# STM8S105C6 register map
Vendor: STMicroelectronics; Series: STM8S/STM8AF, medium density; File version: 1.0
CPU: other r1p0, big endian, no MPU, no FPU
Registers are 8-bit, read-write, reset 0x0 unless marked. A register's access mark holds for its fields unless they carry their own. Offsets are from the block's base; [hi:lo] are bit positions; {n}, {i} and the like mark numbered series.

## ITC_EXTI
Base 0x000050A0
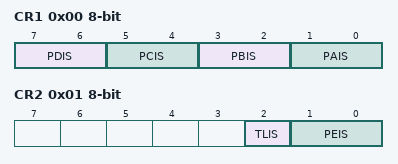
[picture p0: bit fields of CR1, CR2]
0x00 CR1 — External interrupt control register 1
  [7:6] PDIS, [5:4] PCIS, [3:2] PBIS, [1:0] PAIS
0x01 CR2 — External interrupt control register 2
  [2] TLIS, [1:0] PEIS

## ITC_SPR
Base 0x00007F70
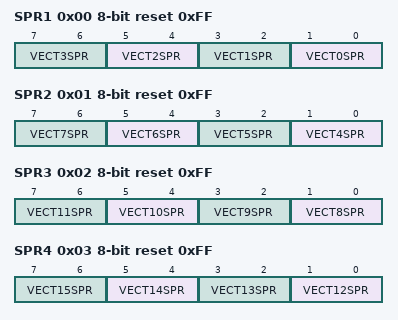
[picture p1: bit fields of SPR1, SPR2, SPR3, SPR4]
0x00 SPR1 reset 0xFF — Interrupt software priority register 1
  [2n+1:2n] VECT{n}SPR (n=0..3)
0x01 SPR2 reset 0xFF — Interrupt software priority register 2
  [2n-7:2n-8] VECT{n}SPR (n=4..7)
0x02 SPR3 reset 0xFF — Interrupt software priority register 3
  [2n-15:2n-16] VECT{n}SPR (n=8..11)
0x03 SPR4 reset 0xFF — Interrupt software priority register 4
  [2n-23:2n-24] VECT{n}SPR (n=12..15)
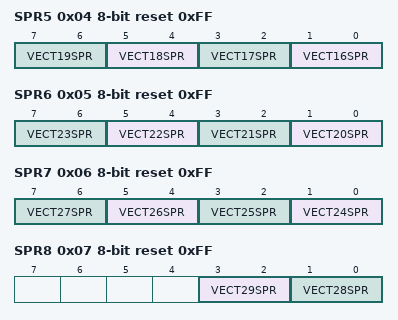
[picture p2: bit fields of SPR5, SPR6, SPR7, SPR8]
0x04 SPR5 reset 0xFF — Interrupt software priority register 5
  [2n-31:2n-32] VECT{n}SPR (n=16..19)
0x05 SPR6 reset 0xFF — Interrupt software priority register 6
  [2n-39:2n-40] VECT{n}SPR (n=20..23)
0x06 SPR7 reset 0xFF — Interrupt software priority register 7
  [2n-47:2n-48] VECT{n}SPR (n=24..27)
0x07 SPR8 reset 0xFF — Interrupt software priority register 8
  [3:2] VECT29SPR, [1:0] VECT28SPR

## IWDG
Base 0x000050E0
0x00 KR — IWDG key register
  [7:0] KEY
0x01 PR — IWDG prescaler register
  [2:0] PR
0x02 RLR reset 0xFF — IWDG reload register
  [7:0] RL

## OPT
Base 0x00004800
0x00 OPT0 — Read-out protection (ROP)
0x01 OPT1 — User boot code (UBC)
0x02 NOPT1 reset 0xFF — User boot code (UBC) (complementary byte)
0x03 OPT2 — Alternate function remapping (AFR)
0x04 NOPT2 reset 0xFF — Alternate function remapping (AFR) (complementary byte)
0x05 OPT3 — Misc. option
0x06 NOPT3 reset 0xFF — Misc. option (complementary byte)
0x07 OPT4 — Clock option
0x08 NOPT4 reset 0xFF — Clock option (complementary byte)
0x09 OPT5 — HSE clock startup
0x0A NOPT5 reset 0xFF — HSE clock startup (complementary byte)
0x7E OPTBL — Bootloader
0x7F NOPTBL reset 0xFF — Bootloader (complementary byte)

## PORTA
Base 0x00005000
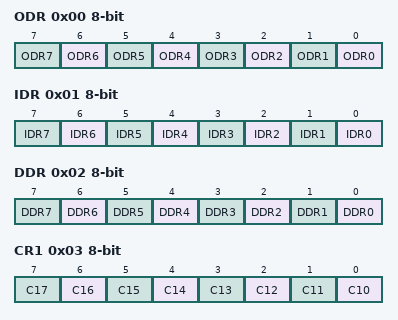
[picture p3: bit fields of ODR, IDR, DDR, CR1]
0x00 ODR — Port A data output latch register
  [n] ODR{n} (n=0..7)
0x01 IDR — Port A input pin value register
  [n] IDR{n} (n=0..7)
0x02 DDR — Port A data direction register
  [n] DDR{n} (n=0..7)
0x03 CR1 — Port A control register 1
  [n-10] C{n} (n=10..17)
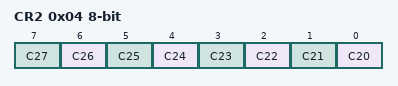
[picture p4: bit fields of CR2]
0x04 CR2 — Port A control register 2
  [n-20] C{n} (n=20..27)

## PORTB
Base 0x00005005
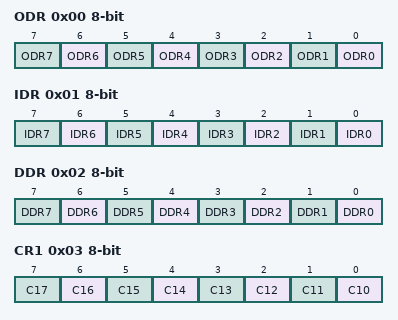
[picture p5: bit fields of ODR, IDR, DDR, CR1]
0x00 ODR — Port B data output latch register
  [n] ODR{n} (n=0..7)
0x01 IDR — Port B input pin value register
  [n] IDR{n} (n=0..7)
0x02 DDR — Port B data direction register
  [n] DDR{n} (n=0..7)
0x03 CR1 — Port B control register 1
  [n-10] C{n} (n=10..17)
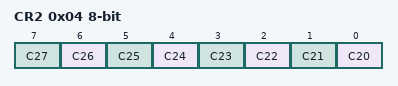
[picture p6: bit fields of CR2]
0x04 CR2 — Port B control register 2
  [n-20] C{n} (n=20..27)

## PORTC
Base 0x0000500A
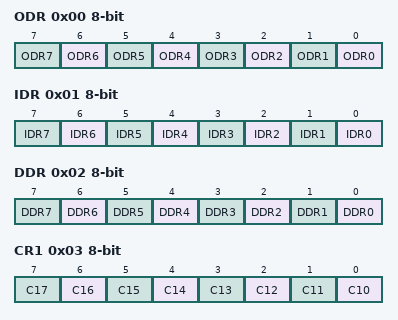
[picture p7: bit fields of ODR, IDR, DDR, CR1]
0x00 ODR — Port C data output latch register
  [n] ODR{n} (n=0..7)
0x01 IDR — Port C input pin value register
  [n] IDR{n} (n=0..7)
0x02 DDR — Port C data direction register
  [n] DDR{n} (n=0..7)
0x03 CR1 — Port C control register 1
  [n-10] C{n} (n=10..17)
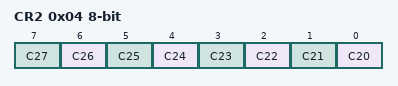
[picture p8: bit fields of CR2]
0x04 CR2 — Port C control register 2
  [n-20] C{n} (n=20..27)

## PORTD
Base 0x0000500F
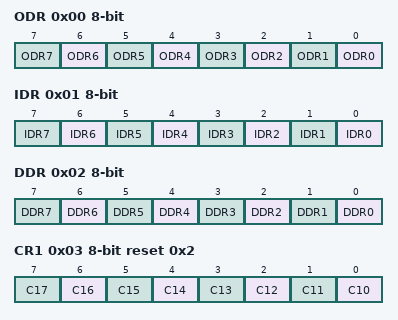
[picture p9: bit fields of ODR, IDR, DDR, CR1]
0x00 ODR — Port D data output latch register
  [n] ODR{n} (n=0..7)
0x01 IDR — Port D input pin value register
  [n] IDR{n} (n=0..7)
0x02 DDR — Port D data direction register
  [n] DDR{n} (n=0..7)
0x03 CR1 reset 0x2 — Port D control register 1
  [n-10] C{n} (n=10..17)
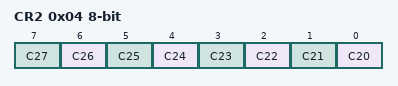
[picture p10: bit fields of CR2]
0x04 CR2 — Port D control register 2
  [n-20] C{n} (n=20..27)

## PORTE
Base 0x00005014
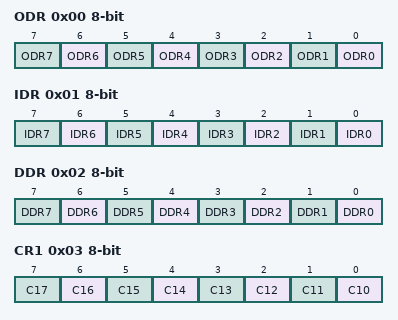
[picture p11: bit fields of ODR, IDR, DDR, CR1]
0x00 ODR — Port E data output latch register
  [n] ODR{n} (n=0..7)
0x01 IDR — Port E input pin value register
  [n] IDR{n} (n=0..7)
0x02 DDR — Port E data direction register
  [n] DDR{n} (n=0..7)
0x03 CR1 — Port E control register 1
  [n-10] C{n} (n=10..17)
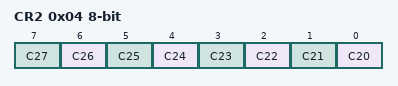
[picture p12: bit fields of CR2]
0x04 CR2 — Port E control register 2
  [n-20] C{n} (n=20..27)
